AUTOSAR XML (schema 4-3-0)
package /fp
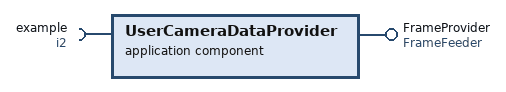
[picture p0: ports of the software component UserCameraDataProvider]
  application sw component type UserCameraDataProvider
    provide port FrameProvider: provided-interface=FrameFeeder
    require port example: required-interface=i2, qwe=rty=uio=val
  sender receiver interface FrameFeeder
